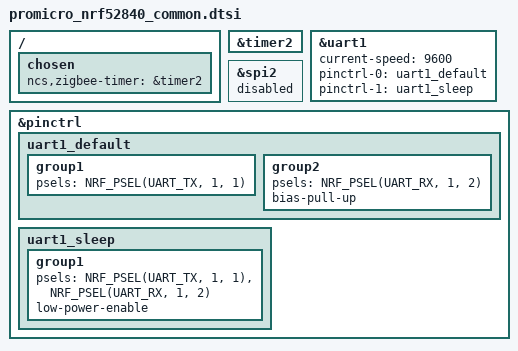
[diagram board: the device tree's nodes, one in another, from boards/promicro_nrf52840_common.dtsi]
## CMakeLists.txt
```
#
# Copyright (c) 2026 Nordic Semiconductor ASA
#
# SPDX-License-Identifier: LicenseRef-Nordic-5-Clause
#

cmake_minimum_required(VERSION 3.20.0)

find_package(Zephyr REQUIRED HINTS $ENV{ZEPHYR_BASE})

project("Zigbee Onkyo AVR controller")

# NORDIC SDK APP START
target_sources(app PRIVATE
  src/main.c
  src/onkyo_iscp.c
)

target_include_directories(app PRIVATE include)
# NORDIC SDK APP END
```

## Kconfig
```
#
# Copyright (c) 2026 Nordic Semiconductor ASA
#
# SPDX-License-Identifier: LicenseRef-Nordic-5-Clause
#

config ONKYO_AVR_MANUFACTURER_CODE
	hex "Manufacturer code of the Onkyo AVR control cluster"
	default 0x1234
	help
	  Manufacturer code that identifies the vendor of the manufacturer
	  specific Onkyo AVR control cluster (0xFC00) and of everything the
	  cluster carries. Clients, such as a Home Assistant quirk or a
	  Zigbee2MQTT converter, address the cluster and its attributes with
	  this code, so they have to be configured with the same value.

	  The default is a placeholder. Set it to the manufacturer code that
	  the Connectivity Standards Alliance assigned to the vendor before
	  shipping a product that is based on this sample.

source "Kconfig.zephyr"
```

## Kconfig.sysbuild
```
#
# Copyright (c) 2026 Nordic Semiconductor
#
# SPDX-License-Identifier: LicenseRef-Nordic-5-Clause
#

source "${ZEPHYR_BASE}/share/sysbuild/Kconfig"

config NRF_DEFAULT_IPC_RADIO
	default y

config NETCORE_IPC_RADIO_IEEE802154
	default y
```

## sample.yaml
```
sample:
  description: Zigbee controller for an Onkyo TX-SR805 AV receiver
  name: Zigbee Onkyo AVR controller
common:
  tags:
    - ci_build
    - smoke
    - sysbuild
    - ci_samples_zigbee
tests:
  sample.zigbee.onkyo_avr:
    sysbuild: true
    build_only: true
    integration_platforms:
      - promicro_nrf52840/nrf52840
    platform_allow:
      - promicro_nrf52840/nrf52840
      - promicro_nrf52840/nrf52840/uf2
```

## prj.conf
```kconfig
#
# Copyright (c) 2026 Nordic Semiconductor ASA
#
# SPDX-License-Identifier: LicenseRef-Nordic-5-Clause
#

CONFIG_NCS_SAMPLES_DEFAULTS=y

CONFIG_UART_INTERRUPT_DRIVEN=y
CONFIG_SERIAL=y
CONFIG_GPIO=y

# Keep printk and the log on the debug interface of the board (USB CDC ACM on
# the Pro Micro nRF52840), UART1 is reserved for the ISCP link.
CONFIG_CONSOLE=y
CONFIG_UART_CONSOLE=y

CONFIG_HEAP_MEM_POOL_SIZE=2048
CONFIG_MAIN_THREAD_PRIORITY=7

CONFIG_ZIGBEE_ADD_ON=y
CONFIG_ZIGBEE_APP_UTILS=y
CONFIG_ZIGBEE_ROLE_ROUTER=y

# The device joins a network that another device created. A coordinator of
# another ecosystem, such as Home Assistant, does not necessarily work on
# channel 16, which is the only channel the default single channel selection
# mode scans.
CONFIG_ZIGBEE_CHANNEL_SELECTION_MODE_MULTI=y

# Scanning all the channels of the channel mask needs one queue element per
# channel, next to the elements that the ISCP link posts.
CONFIG_ZIGBEE_APP_CB_QUEUE_LENGTH=17

# Enable DK LED and Buttons library
CONFIG_DK_LIBRARY=y

# The application callback queue carries the receiver state reported over the
# serial link, and ZBOSS shares the workqueue with the ISCP worker.
CONFIG_SYSTEM_WORKQUEUE_STACK_SIZE=2048
```

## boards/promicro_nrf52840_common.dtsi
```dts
/*
 * Copyright (c) 2026 Nordic Semiconductor ASA
 *
 * SPDX-License-Identifier: LicenseRef-Nordic-5-Clause
 */

/*
 * Board setup that is the same for every promicro_nrf52840 board variant:
 * the Zigbee timer and the ISCP link to the receiver. Included from the
 * per-variant overlays, which add the flash layout they need.
 */

/ {
	chosen {
		ncs,zigbee-timer = &timer2;
	};
};

&timer2 {
	status = "okay";
};

/* ISCP link to the receiver: 9600 baud, 8N1, '!' <unit> <command> <parameter>
 * '\r' frames. The Pro Micro nRF52840 breaks out no dedicated serial port, so
 * the link uses the SPI2 pins, which this application does not need.
 */
&uart1 {
	status = "okay";
	current-speed = <9600>;
	pinctrl-0 = <&uart1_default>;
	pinctrl-1 = <&uart1_sleep>;
	pinctrl-names = "default", "sleep";
};

&spi2 {
	/* Owned by the ISCP UART. */
	status = "disabled";
};

&pinctrl {
	uart1_default: uart1_default {
		group1 {
			psels = <NRF_PSEL(UART_TX, 1, 1)>;
		};

		group2 {
			psels = <NRF_PSEL(UART_RX, 1, 2)>;
			bias-pull-up;
		};
	};

	uart1_sleep: uart1_sleep {
		group1 {
			psels = <NRF_PSEL(UART_TX, 1, 1)>,
				<NRF_PSEL(UART_RX, 1, 2)>;
			low-power-enable;
		};
	};
};
```

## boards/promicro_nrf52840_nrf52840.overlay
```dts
/*
 * Copyright (c) 2026 Nordic Semiconductor ASA
 *
 * SPDX-License-Identifier: LicenseRef-Nordic-5-Clause
 */

#include <nrf52840_partitions.dtsi>
#include "promicro_nrf52840_common.dtsi"
```

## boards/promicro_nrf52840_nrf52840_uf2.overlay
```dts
/*
 * Copyright (c) 2026 Nordic Semiconductor ASA
 *
 * SPDX-License-Identifier: LicenseRef-Nordic-5-Clause
 */

#include "promicro_nrf52840_common.dtsi"

/*
 * Flash layout of the UF2 variant, as it is expected by the Adafruit nRF52
 * bootloader on the Pro Micro nRF52840:
 *
 *   0x00000000 SoftDevice s140 v6   (152 kB)
 *   0x00026000 Application          (776 kB)
 *   0x000e8000 ZBOSS NVRAM          (32 kB)
 *   0x000f0000 ZBOSS product config (4 kB)
 *   0x000f1000 Storage              (12 kB)
 *   0x000f4000 UF2 bootloader       (48 kB)
 *
 * Partition Manager is disabled, so ZBOSS needs the fixed partition nodes
 * zboss_nvram and zboss_product_config in the devicetree, the same way as the
 * nrf52840_partitions.dtsi layout used by the default board variant provides
 * them. The board layout gives all flash up to 0x000f4000 to the application
 * and the storage partition, which leaves no room for the ZBOSS partitions and
 * does not fit the layout that file expects, so the application and storage
 * partitions are resized here to make room.
 *
 * Unlike nrf52840_partitions.dtsi, the partitions below keep the
 * fixed-partitions compatible of the board layout instead of switching to
 * zephyr,mapped-partition. A mapped code partition disables the
 * CONFIG_FLASH_LOAD_OFFSET and CONFIG_FLASH_LOAD_SIZE options, and the UF2
 * conversion uses CONFIG_FLASH_LOAD_OFFSET as the load address of the image.
 */

/delete-node/ &code_partition;
/delete-node/ &storage_partition;

&flash0 {
	partitions {
		code_partition: partition@26000 {
			label = "Application";
			reg = <0x00026000 DT_SIZE_K(776)>;
		};

		zboss_nvram: partition@e8000 {
			label = "zboss-nvram";
			reg = <0x000e8000 DT_SIZE_K(32)>;
		};

		zboss_product_config: partition@f0000 {
			label = "zboss-product-config";
			reg = <0x000f0000 DT_SIZE_K(4)>;
		};

		storage_partition: partition@f1000 {
			label = "Storage";
			reg = <0x000f1000 DT_SIZE_K(12)>;
		};
	};
};
```

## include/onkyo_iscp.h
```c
/*
 * Copyright (c) 2026 Nordic Semiconductor ASA
 *
 * SPDX-License-Identifier: LicenseRef-Nordic-5-Clause
 */

/** @file
 *
 * @brief ISCP (Integra Serial Control Protocol) link to an Onkyo TX-SR805.
 *
 * Commands are plain ASCII: '!' <unit> <command> <parameter> '\r', for example
 * "!1PWR01\r". The TX-SR805 terminates replies with 0x1A. The link runs at
 * 9600 baud, 8 data bits, no parity, 1 stop bit.
 */

#ifndef ONKYO_ISCP_H
#define ONKYO_ISCP_H 1

#include <stdbool.h>
#include <stdint.h>

/** Identifier of the receiver all commands are addressed to. */
#define ONKYO_ISCP_UNIT_ID "1"

/** Master volume range as reported by the receiver with the MVL command. */
#define ONKYO_ISCP_VOLUME_MIN 0x00
#define ONKYO_ISCP_VOLUME_MAX 0x64

/** Input selector values of the TX-SR805 (SLI command). */
#define ONKYO_ISCP_INPUT_CBL_SAT 0x01
#define ONKYO_ISCP_INPUT_GAME_TV 0x02
#define ONKYO_ISCP_INPUT_PC      0x05
#define ONKYO_ISCP_INPUT_BD_DVD  0x10

/** Receiver state as reported back over the link. */
struct onkyo_iscp_state {
	/** Set when the receiver has reported its power state. */
	bool power_valid;
	bool power;
	/** Set when the receiver has reported its mute state. */
	bool mute_valid;
	bool mute;
	/** Set when the receiver has reported the active input. */
	bool input_valid;
	uint8_t input;
	/** Set when the receiver has reported the master volume. */
	bool volume_valid;
	uint8_t volume;
};

/**
 * @brief Callback invoked from thread context when the receiver reports state.
 *
 * @param[in] state  Latest known receiver state.
 */
typedef void (*onkyo_iscp_state_cb_t)(const struct onkyo_iscp_state *state);

/**
 * @brief Initialize the ISCP link.
 *
 * Enables the receiver UART and starts the worker that serializes outgoing
 * commands and parses the replies.
 *
 * @param[in] state_cb  Callback for state reported by the receiver. May be NULL.
 *
 * @retval 0        Link is ready.
 * @retval -ENODEV  The receiver UART is not available.
 */
int onkyo_iscp_init(onkyo_iscp_state_cb_t state_cb);

/**
 * @brief Queue "!1PWR<00|01>", turning the receiver on or into standby.
 *
 * @retval 0         Command queued.
 * @retval -EAGAIN   The transmit queue is full.
 * @retval -ENODEV   The link is not initialized.
 */
int onkyo_iscp_power_set(bool on);

/** @brief Queue "!1PWRQSTN", asking the receiver for its power state. */
int onkyo_iscp_power_query(void);

/**
 * @brief Queue "!1MVL<xx>", setting the master volume.
 *
 * @param[in] volume  Volume in the receiver's 0-100 range.
 */
int onkyo_iscp_volume_set(uint8_t volume);

/**
 * @brief Queue "!1MVL<UP|DOWN>", stepping the master volume by one step.
 *
 * @param[in] up  True to raise, false to lower the volume.
 */
int onkyo_iscp_volume_step(bool up);

/** @brief Queue "!1MVLQSTN", asking the receiver for its master volume. */
int onkyo_iscp_volume_query(void);

/** @brief Queue "!1AMT<00|01>", muting or unmuting the output. */
int onkyo_iscp_mute_set(bool mute);

/** @brief Queue "!1AMTQSTN", asking the receiver for its mute state. */
int onkyo_iscp_mute_query(void);

/**
 * @brief Queue "!1SLI<xx>", selecting an input.
 *
 * @param[in] input  Input selector value, see @ref ONKYO_ISCP_INPUT_CBL_SAT.
 */
int onkyo_iscp_input_select(uint8_t input);

/** @brief Queue "!1SLIQSTN", asking the receiver for the active input. */
int onkyo_iscp_input_query(void);

/** @brief Queue "!1OSDMENU", opening the on-screen display menu. */
int onkyo_iscp_osd_menu(void);

#endif /* ONKYO_ISCP_H */
```

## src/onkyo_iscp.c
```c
/*
 * Copyright (c) 2026 Nordic Semiconductor ASA
 *
 * SPDX-License-Identifier: LicenseRef-Nordic-5-Clause
 */

#include <string.h>

#include <zephyr/device.h>
#include <zephyr/drivers/uart.h>
#include <zephyr/kernel.h>
#include <zephyr/logging/log.h>
#include <zephyr/sys/printk.h>
#include <zephyr/sys/ring_buffer.h>

#include "onkyo_iscp.h"

LOG_MODULE_DECLARE(app, LOG_LEVEL_INF);

/* '!' <unit> <3 character command> <parameter>, the longest parameter is "QSTN". */
#define ISCP_FRAME_MAX_LEN 16

/* Offset of the command within a frame, past '!' and the unit identifier. */
#define ISCP_COMMAND_OFFSET 2
#define ISCP_COMMAND_LEN    3

#define ISCP_START          '!'
#define ISCP_TX_TERMINATOR  '\r'
#define ISCP_RX_TERMINATOR  0x1A

/* Outgoing commands that can wait for the UART to become free. */
#define ISCP_TX_QUEUE_LEN 8

/* Size of the buffer received bytes are collected in before they are parsed. */
#define ISCP_RX_RING_SIZE 64

/* The worker runs below the Zigbee and main threads, it only ever handles
 * serial traffic.
 */
#define ISCP_THREAD_PRIORITY   K_PRIO_PREEMPT(10)
#define ISCP_THREAD_STACK_SIZE 1024

struct iscp_frame {
	char data[ISCP_FRAME_MAX_LEN];
	uint8_t len;
};

static const struct device *const iscp_uart = DEVICE_DT_GET_OR_NULL(DT_NODELABEL(uart1));

K_MSGQ_DEFINE(iscp_tx_queue, sizeof(struct iscp_frame), ISCP_TX_QUEUE_LEN, 1);
RING_BUF_DECLARE(iscp_rx_ring, ISCP_RX_RING_SIZE);
static K_SEM_DEFINE(iscp_work_sem, 0, 1);

static onkyo_iscp_state_cb_t iscp_state_cb;
static struct onkyo_iscp_state iscp_state;

/* Frame being assembled from received bytes, always NUL terminated. */
static char iscp_rx_frame[ISCP_FRAME_MAX_LEN + 1];
static uint8_t iscp_rx_frame_len;

static bool iscp_ready;

static void iscp_wake(void)
{
	(void)k_sem_give(&iscp_work_sem);
}

static bool iscp_parse_bool2(const char *text, bool *value)
{
	if ((text[0] != '0') || ((text[1] != '0') && (text[1] != '1'))) {
		return false;
	}

	*value = (text[1] == '1');

	return true;
}

static bool iscp_parse_hex2(const char *text, uint8_t *value)
{
	uint8_t result = 0U;

	for (uint8_t i = 0U; i < 2U; i++) {
		char digit = text[i];

		result <<= 4;

		if ((digit >= '0') && (digit <= '9')) {
			result |= (uint8_t)(digit - '0');
		} else if ((digit >= 'A') && (digit <= 'F')) {
			result |= (uint8_t)(digit - 'A' + 10);
		} else if ((digit >= 'a') && (digit <= 'f')) {
			result |= (uint8_t)(digit - 'a' + 10);
		} else {
			return false;
		}
	}

	*value = result;

	return true;
}

static void iscp_handle_frame(const char *frame, uint8_t len)
{
	const char *command;
	const char *parameter;
	uint8_t parameter_len;
	bool bool_value;
	uint8_t value;
	bool changed = false;

	LOG_INF("ISCP RX: %s", frame);

	if (len < (ISCP_COMMAND_OFFSET + ISCP_COMMAND_LEN)) {
		return;
	}

	command = frame + ISCP_COMMAND_OFFSET;
	parameter = command + ISCP_COMMAND_LEN;
	parameter_len = len - (ISCP_COMMAND_OFFSET + ISCP_COMMAND_LEN);

	if ((strncmp(command, "PWR", ISCP_COMMAND_LEN) == 0) && (parameter_len >= 2U) &&
	    iscp_parse_bool2(parameter, &bool_value)) {
		iscp_state.power = bool_value;
		iscp_state.power_valid = true;
		changed = true;
	} else if ((strncmp(command, "AMT", ISCP_COMMAND_LEN) == 0) && (parameter_len >= 2U) &&
		   iscp_parse_bool2(parameter, &bool_value)) {
		iscp_state.mute = bool_value;
		iscp_state.mute_valid = true;
		changed = true;
	} else if ((strncmp(command, "MVL", ISCP_COMMAND_LEN) == 0) && (parameter_len >= 2U) &&
		   iscp_parse_hex2(parameter, &value)) {
		iscp_state.volume = value;
		iscp_state.volume_valid = true;
		changed = true;
	} else if ((strncmp(command, "SLI", ISCP_COMMAND_LEN) == 0) && (parameter_len >= 2U) &&
		   iscp_parse_hex2(parameter, &value)) {
		iscp_state.input = value;
		iscp_state.input_valid = true;
		changed = true;
	}

	if (changed && (iscp_state_cb != NULL)) {
		iscp_state_cb(&iscp_state);
	}
}

static void iscp_rx_byte(char byte)
{
	if (byte == ISCP_START) {
		iscp_rx_frame[0] = byte;
		iscp_rx_frame_len = 1U;
		return;
	}

	if (iscp_rx_frame_len == 0U) {
		/* Not inside a frame, ignore the byte. */
		return;
	}

	/* The TX-SR805 terminates replies with SUB (0x1A). Accept CR too for
	 * compatibility with receivers that use the documented terminator.
	 */
	if ((byte == ISCP_RX_TERMINATOR) || (byte == ISCP_TX_TERMINATOR)) {
		iscp_rx_frame[iscp_rx_frame_len] = '\0';
		iscp_handle_frame(iscp_rx_frame, iscp_rx_frame_len);
		iscp_rx_frame_len = 0U;
		return;
	}

	if (iscp_rx_frame_len < ISCP_FRAME_MAX_LEN) {
		iscp_rx_frame[iscp_rx_frame_len++] = byte;
	} else {
		/* Longer than any expected reply, drop the frame. */
		iscp_rx_frame_len = 0U;
	}
}

static void iscp_uart_isr(const struct device *dev, void *user_data)
{
	uint8_t chunk[16];
	int received;

	ARG_UNUSED(user_data);

	while (uart_irq_update(dev) && uart_irq_is_pending(dev)) {
		if (!uart_irq_rx_ready(dev)) {
			break;
		}

		do {
			received = uart_fifo_read(dev, chunk, sizeof(chunk));
			if (received > 0) {
				(void)ring_buf_put(&iscp_rx_ring, chunk, (uint32_t)received);
			}
		} while (received > 0);
	}

	iscp_wake();
}

static void iscp_pump_rx(void)
{
	uint8_t chunk[16];
	uint32_t len;

	do {
		len = ring_buf_get(&iscp_rx_ring, chunk, sizeof(chunk));

		for (uint32_t i = 0U; i < len; i++) {
			iscp_rx_byte((char)chunk[i]);
		}
	} while (len > 0U);
}

static void iscp_pump_tx(void)
{
	struct iscp_frame frame;

	while (k_msgq_get(&iscp_tx_queue, &frame, K_NO_WAIT) == 0) {
		for (uint8_t i = 0U; i < frame.len; i++) {
			uart_poll_out(iscp_uart, (uint8_t)frame.data[i]);
		}
	}
}

static void iscp_thread_fn(void *p1, void *p2, void *p3)
{
	ARG_UNUSED(p1);
	ARG_UNUSED(p2);
	ARG_UNUSED(p3);

	for (;;) {
		(void)k_sem_take(&iscp_work_sem, K_FOREVER);

		iscp_pump_rx();
		iscp_pump_tx();
	}
}

K_THREAD_DEFINE(iscp_thread, ISCP_THREAD_STACK_SIZE, iscp_thread_fn, NULL, NULL, NULL,
		ISCP_THREAD_PRIORITY, 0, 0);

static int iscp_send(const char *command, const char *parameter)
{
	struct iscp_frame frame;
	int len;

	if (!iscp_ready) {
		return -ENODEV;
	}

	len = snprintk(frame.data, sizeof(frame.data), "%c%s%s%s%c", ISCP_START,
		       ONKYO_ISCP_UNIT_ID, command, parameter, ISCP_TX_TERMINATOR);
	if ((len < 0) || (len >= (int)sizeof(frame.data))) {
		LOG_ERR("ISCP command %s%s does not fit in a frame", command, parameter);
		return -EINVAL;
	}

	frame.len = (uint8_t)len;

	if (k_msgq_put(&iscp_tx_queue, &frame, K_NO_WAIT) != 0) {
		LOG_WRN("ISCP transmit queue full, dropping %s%s", command, parameter);
		return -EAGAIN;
	}

	LOG_INF("ISCP TX: %s%s", command, parameter);

	iscp_wake();

	return 0;
}

static int iscp_send_hex2(const char *command, uint8_t value)
{
	char parameter[3];

	(void)snprintk(parameter, sizeof(parameter), "%02X", value);

	return iscp_send(command, parameter);
}

int onkyo_iscp_init(onkyo_iscp_state_cb_t state_cb)
{
	if (iscp_uart == NULL) {
		LOG_ERR("Receiver UART is not enabled in the devicetree");
		return -ENODEV;
	}

	if (!device_is_ready(iscp_uart)) {
		LOG_ERR("Receiver UART is not ready");
		return -ENODEV;
	}

	iscp_state_cb = state_cb;

	uart_irq_callback_set(iscp_uart, iscp_uart_isr);
	uart_irq_rx_enable(iscp_uart);

	iscp_ready = true;

	return 0;
}

int onkyo_iscp_power_set(bool on)
{
	return iscp_send("PWR", on ? "01" : "00");
}

int onkyo_iscp_power_query(void)
{
	return iscp_send("PWR", "QSTN");
}

int onkyo_iscp_volume_set(uint8_t volume)
{
	if (volume > ONKYO_ISCP_VOLUME_MAX) {
		volume = ONKYO_ISCP_VOLUME_MAX;
	}

	return iscp_send_hex2("MVL", volume);
}

int onkyo_iscp_volume_step(bool up)
{
	return iscp_send("MVL", up ? "UP" : "DOWN");
}

int onkyo_iscp_volume_query(void)
{
	return iscp_send("MVL", "QSTN");
}

int onkyo_iscp_mute_set(bool mute)
{
	return iscp_send("AMT", mute ? "01" : "00");
}

int onkyo_iscp_mute_query(void)
{
	return iscp_send("AMT", "QSTN");
}

int onkyo_iscp_input_select(uint8_t input)
{
	return iscp_send_hex2("SLI", input);
}

int onkyo_iscp_input_query(void)
{
	return iscp_send("SLI", "QSTN");
}

int onkyo_iscp_osd_menu(void)
{
	return iscp_send("OSD", "MENU");
}
```
